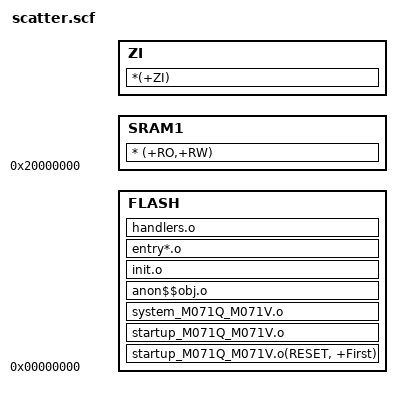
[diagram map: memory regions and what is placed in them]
FLASH 0x00000000
{
    FLASH +0
    {
        startup_M071Q_M071V.o(RESET, +First)
        startup_M071Q_M071V.o
        system_M071Q_M071V.o
        anon$$obj.o
        init.o
        entry*.o
        handlers.o
    }

    SRAM1 0x20000000
    {
        * (+RO,+RW)
    }

    ZI +0
    {
        *(+ZI)
    }

}

